# MKW40Z4 register map
Vendor: Freescale Semiconductor, Inc.; Series: Kinetis_W; File version: 1.6
CPU: CM0PLUS r0p0, little endian, no MPU, no FPU, VTOR, 2 interrupt priority bits
Registers are 32-bit, read-write, reset 0x0 unless marked. A register's access mark holds for its fields unless they carry their own. Offsets are from the block's base; [hi:lo] are bit positions; {n}, {i} and the like mark numbered series; 'fields as' and 'values as' point back to an identical list.

## XCVR (part 1 of 2) — Apache 1.0 Transceiver
Base 0x4005C000; register names take the prefix XCVR_
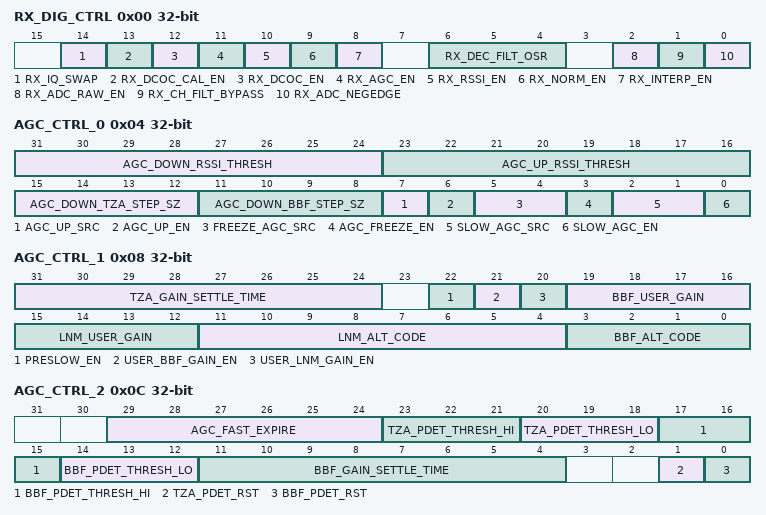
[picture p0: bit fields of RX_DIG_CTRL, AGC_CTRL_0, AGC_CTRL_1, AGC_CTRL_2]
0x00 RX_DIG_CTRL — RX Digital Control
  [14] RX_IQ_SWAP
    0=IQ swap is disabled; 1=IQ swap is enabled
  [13] RX_DCOC_CAL_EN — DCOC Calibration Enable
    0=DCOC calibration is disabled; 1=DCOC calibration is enabled
  [12] RX_DCOC_EN — DCOC Enable
    0=DCOC is disabled; 1=DCOC is enabled
  [11] RX_AGC_EN — AGC Global Enable
    0=AGC is disabled; 1=AGC is enabled
  [10] RX_RSSI_EN — RSSI Measurement Enable
    0=RSSI measurement is disabled; 1=RSSI measurement is enabled
  [9] RX_NORM_EN — Normalizer Enable
    0=Normalizer is disabled; 1=Normalizer is enabled
  [8] RX_INTERP_EN — Interpolator Enable
    0=Interpolator is disabled; 1=Interpolator is enabled
  [6:4] RX_DEC_FILT_OSR — Decimation Filter Oversampling
    0=OSR 2; 1=OSR 4
  [2] RX_ADC_RAW_EN — ADC Raw Mode selection
    0=Normal operation; 1=The decimation filter's 12bit output consists of two unfiltered 5-bit ADC samples. This is for test purposes only to observe ADC output via XCVR DMA or DTEST.
  [1] RX_CH_FILT_BYPASS — Receive Channel Filter Bypass
    0=Channel filter is enabled; 1=Disable and bypass channel filter
  [0] RX_ADC_NEGEDGE — Receive ADC Negative Edge Selection
    0=Register ADC data on positive edge of clock; 1=Register ADC data on negative edge of clock
0x04 AGC_CTRL_0 — AGC Control 0
  [31:24] AGC_DOWN_RSSI_THRESH — AGC DOWN RSSI Threshold
  [23:16] AGC_UP_RSSI_THRESH — AGC UP RSSI Threshold
  [15:12] AGC_DOWN_TZA_STEP_SZ
  [11:8] AGC_DOWN_BBF_STEP_SZ
  [7] AGC_UP_SRC — AGC Up Source
    0=PDET LO; 1=RSSI
  [6] AGC_UP_EN — AGC Up Enable
  [5:4] FREEZE_AGC_SRC — Freeze AGC Source Selection
    0=BTLE Preamble Detect; 1=Zigbee Preamble Detect
  [3] AGC_FREEZE_EN — AGC Freeze Enable
  [2:1] SLOW_AGC_SRC — Slow AGC Source Selection
    0=BTLE Preamble Detect; 1=Zigbee Preamble Detect
  [0] SLOW_AGC_EN — Slow AGC Enable
0x08 AGC_CTRL_1 — AGC Control 1
  [31:24] TZA_GAIN_SETTLE_TIME
  [22] PRESLOW_EN — Pre-slow Enable
    0=Pre-slow is disabled; 1=Pre-slow is enabled
  [21] USER_BBF_GAIN_EN — User BBF Gain Enable
  [20] USER_LNM_GAIN_EN — User LNM Gain Enable
  [19:16] BBF_USER_GAIN
  [15:12] LNM_USER_GAIN
  [11:4] LNM_ALT_CODE
  [3:0] BBF_ALT_CODE
0x0C AGC_CTRL_2 — AGC Control 2
  [29:24] AGC_FAST_EXPIRE
  [23:21] TZA_PDET_THRESH_HI — TZA PDET Threshold High
    0=0.6V; 1=0.675V; 2=0.75V; 3=0.825V; 4=0.9V; 5=0.975V; 6=1.05V; 7=1.125V
  [20:18] TZA_PDET_THRESH_LO — TZA PDET Threshold Low
    values as TZA_PDET_THRESH_HI
  [17:15] BBF_PDET_THRESH_HI — BBF PDET Threshold High
    values as TZA_PDET_THRESH_HI
  [14:12] BBF_PDET_THRESH_LO — BBF PDET Threshold Low
    values as TZA_PDET_THRESH_HI
  [11:4] BBF_GAIN_SETTLE_TIME
  [1] TZA_PDET_RST — TZA PDET Reset
  [0] BBF_PDET_RST — BBF PDET Reset
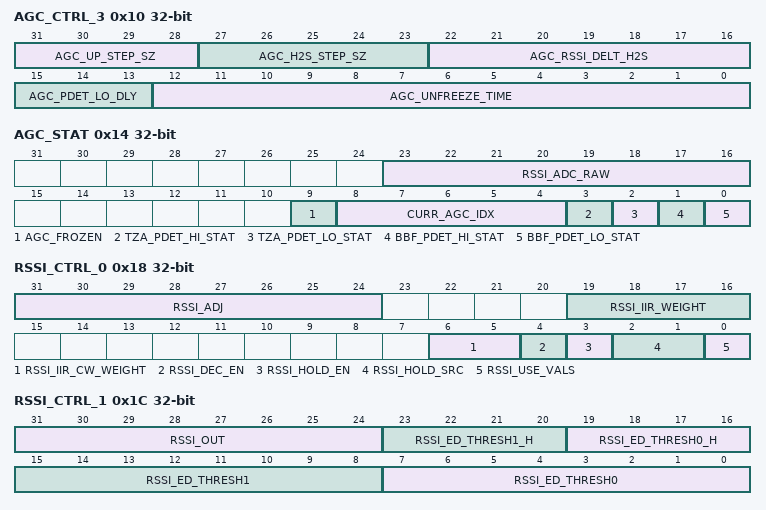
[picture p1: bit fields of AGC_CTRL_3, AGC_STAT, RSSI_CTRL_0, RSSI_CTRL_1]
0x10 AGC_CTRL_3 — AGC Control 3
  [31:28] AGC_UP_STEP_SZ — AGC Up Step Size
  [27:23] AGC_H2S_STEP_SZ
  [22:16] AGC_RSSI_DELT_H2S
  [15:13] AGC_PDET_LO_DLY — AGC Peak Detect Low Delay
  [12:0] AGC_UNFREEZE_TIME
0x14 AGC_STAT ro — AGC Status
  [23:16] RSSI_ADC_RAW — ADC RAW RSSI Reading
  [9] AGC_FROZEN — AGC Frozen Status
    0=AGC is not frozen; 1=AGC is frozen
  [8:4] CURR_AGC_IDX — Current AGC Gain Index
  [3] TZA_PDET_HI_STAT — TZA Peak Detector High Status
  [2] TZA_PDET_LO_STAT — TZA Peak Detector Low Status
  [1] BBF_PDET_HI_STAT — BBF Peak Detector High Status
  [0] BBF_PDET_LO_STAT — BBF Peak Detector Low Status
0x18 RSSI_CTRL_0 — RSSI Control 0
  [31:24] RSSI_ADJ — RSSI Adjustment
  [19:16] RSSI_IIR_WEIGHT — RSSI IIR Weighting
    0=Bypass; 1=1/2
  [6:5] RSSI_IIR_CW_WEIGHT — RSSI IIR CW Weighting
    0=Bypass; 1=1/8
  [4] RSSI_DEC_EN — RSSI Decimation Enable
  [3] RSSI_HOLD_EN — RSSI Hold Enable
  [2:1] RSSI_HOLD_SRC — Hold RSSI Source Selection
    0=BTLE Preamble Detect; 1=Zigbee Preamble Detect
  [0] RSSI_USE_VALS — RSSI Values Selection
0x1C RSSI_CTRL_1 — RSSI Control 1
  [31:24] RSSI_OUT ro — RSSI Reading
  [23:20] RSSI_ED_THRESH1_H — RSSI Energy Detect 1 Hysteresis
  [19:16] RSSI_ED_THRESH0_H — RSSI Energy Detect 0 Hysteresis
  [15:8] RSSI_ED_THRESH1 — RSSI Energy Detect 1 Threshold
  [7:0] RSSI_ED_THRESH0 — RSSI Energy Detect 0 Threshold
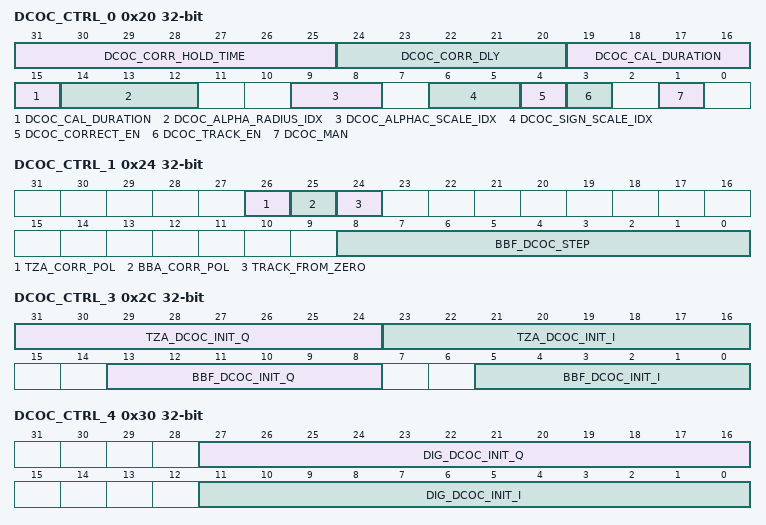
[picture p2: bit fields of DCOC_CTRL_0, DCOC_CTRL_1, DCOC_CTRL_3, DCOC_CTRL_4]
0x20 DCOC_CTRL_0 — DCOC Control 0
  [31:25] DCOC_CORR_HOLD_TIME — DCOC Correction Hold Time
  [24:20] DCOC_CORR_DLY — DCOC Correction Delay
  [19:15] DCOC_CAL_DURATION — DCOC Calibration Duration
  [14:12] DCOC_ALPHA_RADIUS_IDX — Alpha-R Scaling
    0=1; 1=1/2; 2=1/4; 3=1/8; 4=1/16; 5=1/32; 6=1/64
  [9:8] DCOC_ALPHAC_SCALE_IDX — DCOC Alpha-C Scaling
    0=1/2; 1=1/4; 2=1/8; 3=1/16
  [6:5] DCOC_SIGN_SCALE_IDX — DCOC Sign Scaling
    0=1/4; 1=1/8; 2=1/16; 3=1/32
  [4] DCOC_CORRECT_EN — DCOC Correction Enable
  [3] DCOC_TRACK_EN — DCOC Tracking Enable
  [1] DCOC_MAN — DCOC Manual Override
0x24 DCOC_CTRL_1 — DCOC Control 1
  [26] TZA_CORR_POL — TZA Correction Polarity
    0=Normal polarity; 1=Negative polarity. This should be set if the ADC output is inverted, or if the TZA DACs were implemented with negative polarity.
  [25] BBA_CORR_POL — BBA Correction Polarity
    0=Normal polarity; 1=Negative polarity. This should be set if the ADC output is inverted, or if the BBA DACs were implemented with negative polarity.
  [24] TRACK_FROM_ZERO
    0=Track from current I/Q sample; 1=Track from zero
  [8:0] BBF_DCOC_STEP — DCOC BBF Step Size
0x28 DCOC_CTRL_2 — DCOC Control 2
  [12:0] BBF_DCOC_STEP_RECIP — DCOC BBF Reciprocal of Step Size
0x2C DCOC_CTRL_3 — DCOC Control 3
  [31:24] TZA_DCOC_INIT_Q — DCOC TZA Init Q
  [23:16] TZA_DCOC_INIT_I — DCOC TZA Init I
  [13:8] BBF_DCOC_INIT_Q — DCOC BBF Init Q
  [5:0] BBF_DCOC_INIT_I — DCOC BBF Init I
0x30 DCOC_CTRL_4 — DCOC Control 4
  [27:16] DIG_DCOC_INIT_Q — DCOC DIG Init Q
  [11:0] DIG_DCOC_INIT_I — DCOC DIG Init I
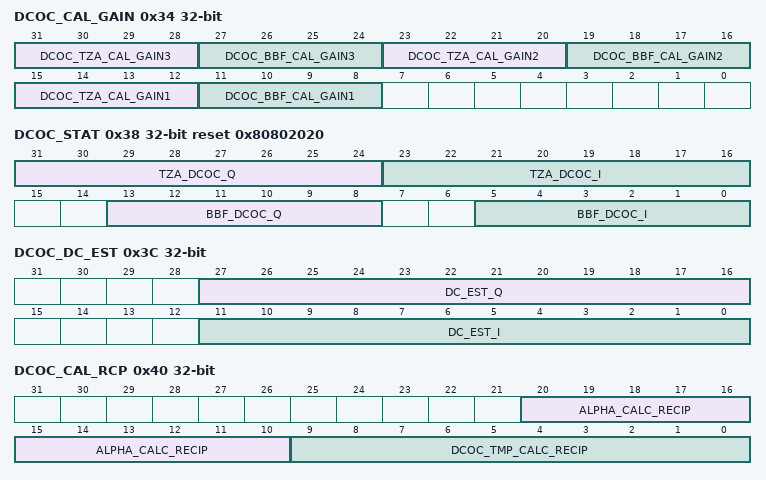
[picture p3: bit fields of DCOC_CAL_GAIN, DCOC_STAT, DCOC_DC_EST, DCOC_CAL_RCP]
0x34 DCOC_CAL_GAIN — DCOC Calibration Gain
  [31:28] DCOC_TZA_CAL_GAIN3 — DCOC TZA Calibration Gain 3
  [27:24] DCOC_BBF_CAL_GAIN3 — DCOC BBF Calibration Gain 3
  [23:20] DCOC_TZA_CAL_GAIN2 — DCOC TZA Calibration Gain 2
  [19:16] DCOC_BBF_CAL_GAIN2 — DCOC BBF Calibration Gain 2
  [15:12] DCOC_TZA_CAL_GAIN1 — DCOC TZA Calibration Gain 1
  [11:8] DCOC_BBF_CAL_GAIN1 — DCOC BBF Calibration Gain 1
0x38 DCOC_STAT ro reset 0x80802020 — DCOC Status
  [31:24] TZA_DCOC_Q — DCOC TZA DAC Q
  [23:16] TZA_DCOC_I — DCOC TZA DAC I
  [13:8] BBF_DCOC_Q — DCOC BBF DAC Q
  [5:0] BBF_DCOC_I — DCOC BBF DAC I
0x3C DCOC_DC_EST ro — DCOC DC Estimate
  [27:16] DC_EST_Q — DCOC DC Estimate Q
  [11:0] DC_EST_I — DCOC DC Estimate I
0x40 DCOC_CAL_RCP — DCOC Calibration Reciprocals
  [20:10] ALPHA_CALC_RECIP — Alpha Calculation Reciprocal
  [9:0] DCOC_TMP_CALC_RECIP — DCOC Calculation Reciprocal
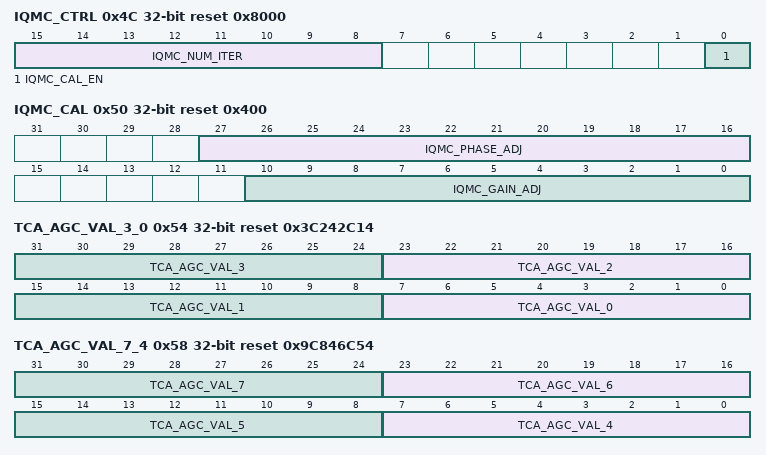
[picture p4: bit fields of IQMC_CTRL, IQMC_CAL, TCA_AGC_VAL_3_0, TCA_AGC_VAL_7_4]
0x4C IQMC_CTRL reset 0x8000 — IQMC Control
  [15:8] IQMC_NUM_ITER — IQ Mismatch Cal Num Iter
  [0] IQMC_CAL_EN — IQ Mismatch Cal Enable
0x50 IQMC_CAL reset 0x400 — IQMC Calibration
  [27:16] IQMC_PHASE_ADJ — IQ Mismatch Correction Phase Coeff
  [10:0] IQMC_GAIN_ADJ — IQ Mismatch Correction Gain Coeff
0x54 TCA_AGC_VAL_3_0 reset 0x3C242C14 — TCA AGC Step Values 3..0
  [8n+7:8n] TCA_AGC_VAL_{n} (n=0..3) — TCA_AGC step {n}
0x58 TCA_AGC_VAL_7_4 reset 0x9C846C54 — TCA AGC Step Values 7..4
  [8n-25:8n-32] TCA_AGC_VAL_{n} (n=4..7) — TCA_AGC step {n}
0x5C TCA_AGC_VAL_8 reset 0xB4 — TCA AGC Step Values 8
  [7:0] TCA_AGC_VAL_8 — TCA_AGC step 8
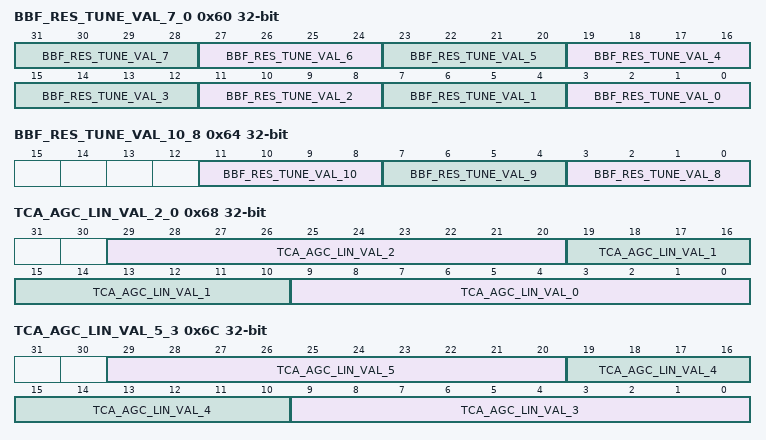
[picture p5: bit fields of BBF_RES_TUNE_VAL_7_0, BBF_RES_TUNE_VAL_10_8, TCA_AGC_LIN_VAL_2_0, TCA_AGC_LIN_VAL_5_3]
0x60 BBF_RES_TUNE_VAL_7_0 — BBF Resistor Tune Values 7..0
  [4n+3:4n] BBF_RES_TUNE_VAL_{n} (n=0..7) — BBF Resistor Tune Step {n}
0x64 BBF_RES_TUNE_VAL_10_8 — BBF Resistor Tune Values 10..8
  [11:8] BBF_RES_TUNE_VAL_10 — BBF Resistor Tune Step 10
  [7:4] BBF_RES_TUNE_VAL_9 — BBF Resistor Tune Step 9
  [3:0] BBF_RES_TUNE_VAL_8 — BBF Resistor Tune Step 8
0x68 TCA_AGC_LIN_VAL_2_0 — TCA AGC Linear Gain Values 2..0
  [29:20] TCA_AGC_LIN_VAL_2 — TCA AGC Linear Gain Step 2
  [19:10] TCA_AGC_LIN_VAL_1 — TCA AGC Linear Gain Step 1
  [9:0] TCA_AGC_LIN_VAL_0 — LNM linear gain value for index 0, e.g. nominal value is 10^(-3/20). Stored with 2 fractional bits, e.g. round([10^(-3/20)]*2^2) = 3decimal
0x6C TCA_AGC_LIN_VAL_5_3 — TCA AGC Linear Gain Values 5..3
  [29:20] TCA_AGC_LIN_VAL_5 — TCA AGC Linear Gain Step 5
  [19:10] TCA_AGC_LIN_VAL_4 — TCA AGC Linear Gain Step 4
  [9:0] TCA_AGC_LIN_VAL_3 — TCA AGC Linear Gain Step 3
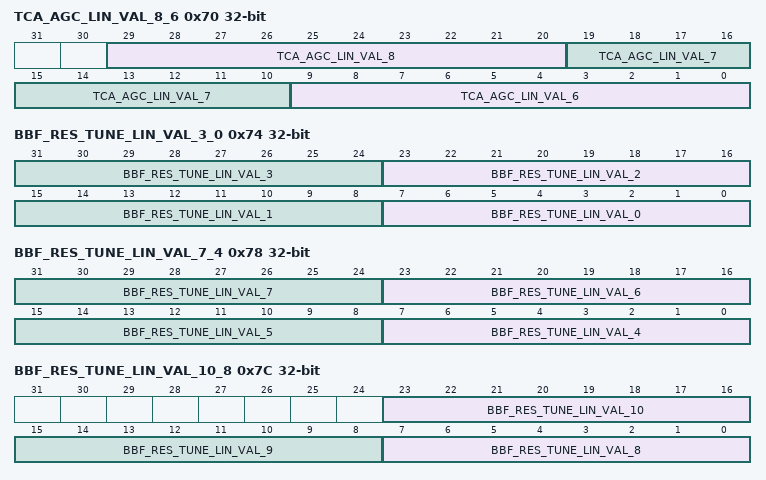
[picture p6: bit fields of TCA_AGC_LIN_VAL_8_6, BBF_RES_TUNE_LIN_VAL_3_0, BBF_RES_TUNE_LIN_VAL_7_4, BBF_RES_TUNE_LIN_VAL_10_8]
0x70 TCA_AGC_LIN_VAL_8_6 — TCA AGC Linear Gain Values 8..6
  [29:20] TCA_AGC_LIN_VAL_8 — TCA AGC Linear Gain Step 8
  [19:10] TCA_AGC_LIN_VAL_7 — TCA AGC Linear Gain Step 7
  [9:0] TCA_AGC_LIN_VAL_6 — TCA AGC Linear Gain Step 6
0x74 BBF_RES_TUNE_LIN_VAL_3_0 — BBF Resistor Tune Values 3..0
  [8n+7:8n] BBF_RES_TUNE_LIN_VAL_{n} (n=0..3) — BBF Resistor Tune Linear Gain Step {n}
0x78 BBF_RES_TUNE_LIN_VAL_7_4 — BBF Resistor Tune Values 7..4
  [8n-25:8n-32] BBF_RES_TUNE_LIN_VAL_{n} (n=4..7) — BBF Resistor Tune Linear Gain Step {n}
0x7C BBF_RES_TUNE_LIN_VAL_10_8 — BBF Resistor Tune Values 10..8
  [23:16] BBF_RES_TUNE_LIN_VAL_10 — BBF Resistor Tune Linear Gain Step 10
  [15:8] BBF_RES_TUNE_LIN_VAL_9 — BBF Resistor Tune Linear Gain Step 9
  [7:0] BBF_RES_TUNE_LIN_VAL_8 — BBF Resistor Tune Linear Gain Step 8
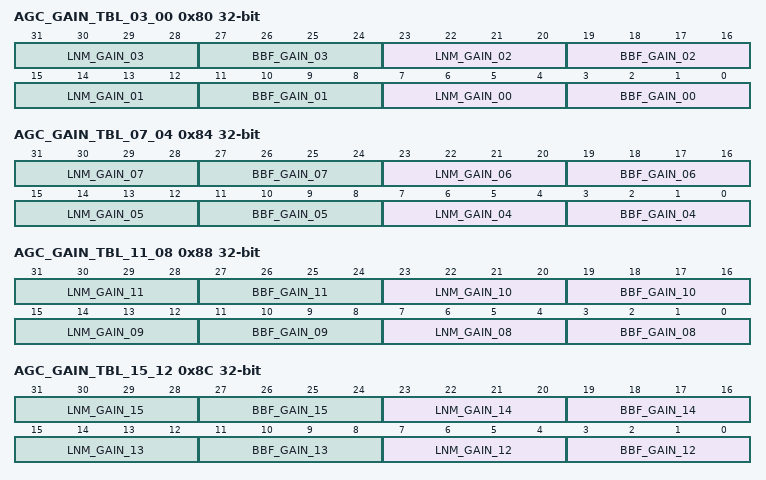
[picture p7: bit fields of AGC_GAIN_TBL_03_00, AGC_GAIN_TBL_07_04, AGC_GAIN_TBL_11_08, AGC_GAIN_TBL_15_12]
0x80 AGC_GAIN_TBL_03_00 — AGC Gain Tables Step 03..00
  [8n+7:8n+4] LNM_GAIN_{n:02} (n=0..3), [8n+3:8n] BBF_GAIN_{n:02} (n=0..3)
0x84 AGC_GAIN_TBL_07_04 — AGC Gain Tables Step 07..04
  [8n-25:8n-28] LNM_GAIN_{n:02} (n=4..7), [8n-29:8n-32] BBF_GAIN_{n:02} (n=4..7)
0x88 AGC_GAIN_TBL_11_08 — AGC Gain Tables Step 11..08
  [8n-57:8n-60] LNM_GAIN_{n:02} (n=8..11), [8n-61:8n-64] BBF_GAIN_{n:02} (n=8..11)
0x8C AGC_GAIN_TBL_15_12 — AGC Gain Tables Step 15..12
  [8n-89:8n-92] LNM_GAIN_{n} (n=12..15), [8n-93:8n-96] BBF_GAIN_{n} (n=12..15)
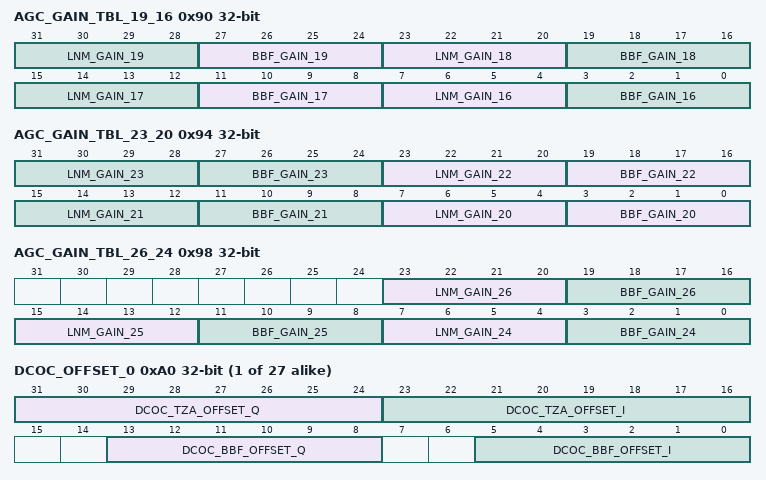
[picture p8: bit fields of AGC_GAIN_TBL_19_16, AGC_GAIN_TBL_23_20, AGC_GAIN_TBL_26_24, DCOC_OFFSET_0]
0x90 AGC_GAIN_TBL_19_16 — AGC Gain Tables Step 19..16
  [8n-121:8n-124] LNM_GAIN_{n} (n=16..19)
  [27:24] BBF_GAIN_19 — BBF Gain 193
  [19:16] BBF_GAIN_18
  [11:8] BBF_GAIN_17
  [3:0] BBF_GAIN_16
0x94 AGC_GAIN_TBL_23_20 — AGC Gain Tables Step 23..20
  [8n-153:8n-156] LNM_GAIN_{n} (n=20..23), [8n-157:8n-160] BBF_GAIN_{n} (n=20..23)
0x98 AGC_GAIN_TBL_26_24 — AGC Gain Tables Step 26..24
  [23:20] LNM_GAIN_26, [19:16] BBF_GAIN_26, [15:12] LNM_GAIN_25, [11:8] BBF_GAIN_25, [7:4] LNM_GAIN_24, [3:0] BBF_GAIN_24
{0xA0+4i} DCOC_OFFSET_{i} (i=0..26)
  [31:24] DCOC_TZA_OFFSET_Q — DCOC TZA Q-channel offset
  [23:16] DCOC_TZA_OFFSET_I — DCOC TZA I-channel offset
  [13:8] DCOC_BBF_OFFSET_Q — DCOC BBF Q-channel offset
  [5:0] DCOC_BBF_OFFSET_I — DCOC BBF I-channel offset
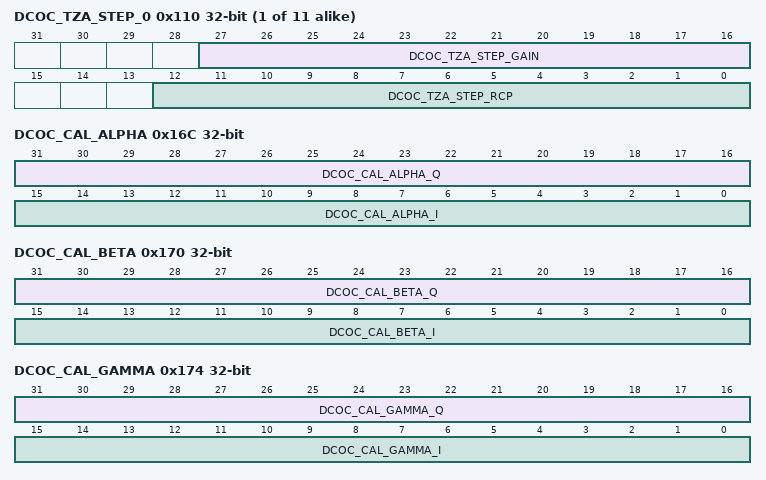
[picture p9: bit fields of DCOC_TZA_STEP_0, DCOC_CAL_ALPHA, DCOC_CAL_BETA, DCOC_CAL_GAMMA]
{0x110+4i} DCOC_TZA_STEP_{i} (i=0..10) — DCOC TZA DC step
  [27:16] DCOC_TZA_STEP_GAIN, [12:0] DCOC_TZA_STEP_RCP
0x16C DCOC_CAL_ALPHA ro — DCOC Calibration Alpha
  [31:16] DCOC_CAL_ALPHA_Q
  [15:0] DCOC_CAL_ALPHA_I — DCOC Calibration I-channel ALPHA constant
0x170 DCOC_CAL_BETA ro — DCOC Calibration Beta
  [31:16] DCOC_CAL_BETA_Q, [15:0] DCOC_CAL_BETA_I
0x174 DCOC_CAL_GAMMA ro — DCOC Calibration Gamma
  [31:16] DCOC_CAL_GAMMA_Q, [15:0] DCOC_CAL_GAMMA_I
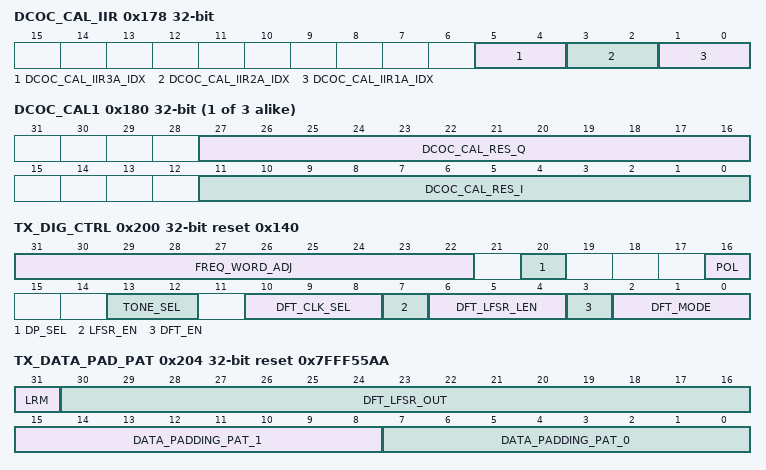
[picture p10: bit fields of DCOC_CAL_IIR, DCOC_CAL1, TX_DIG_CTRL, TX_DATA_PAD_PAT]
0x178 DCOC_CAL_IIR — DCOC Calibration IIR
  [5:4] DCOC_CAL_IIR3A_IDX — DCOC Calibration IIR 3A Index
    0=1/4; 1=1/8
  [3:2] DCOC_CAL_IIR2A_IDX — DCOC Calibration IIR 2A Index
    0=1/1; 1=1/4
  [1:0] DCOC_CAL_IIR1A_IDX — DCOC Calibration IIR 1A Index
    0=1/1; 1=1/4
{0x17C+4i} DCOC_CAL{i} (i=1..3) ro — DCOC Calibration Result
  [27:16] DCOC_CAL_RES_Q — DCOC Calibration Result - Q Channel
  [11:0] DCOC_CAL_RES_I — DCOC Calibration Result - I Channel
{0x1A0+4i} RX_CHF_COEF{i} (i=0..7) — Receive Channel Filter Coefficient
  [7:0] RX_CH_FILT_HX — RX Channel Filter Coefficient
0x200 TX_DIG_CTRL reset 0x140 — TX Digital Control
  [31:22] FREQ_WORD_ADJ — GFSK Frequency Word Adjustment
  [20] DP_SEL — Data Padding Pattern Select
    0=Selects DATA_PADDING_PATTERN_0 as the source for data padding; 1=Selects DATA_PADDING_PATTERN_1 as the source for data padding
  [16] POL — Oversample Clock Capture Polarity
    0=Selects Even clock cycle; 1=Selects Odd clock cycle, a one cycle delay
  [13:12] TONE_SEL — DFT Tone Selection
    {v}=DFT Tone {v} (v=0..3)
  [10:8] DFT_CLK_SEL — DFT Clock Selection
    0=62.5 kHz; 1=125 kHz; 2=250 kHz; 3=500 kHz; 4=1 MHz; 5=2 MHz; 6=4 MHz; 7=Clock is off
  [7] LFSR_EN — DFT LFSR Enable
  [6:4] DFT_LFSR_LEN — DFT LFSR Length
    0=LFSR 9, tap mask 100010000; 1=LFSR 10, tap mask 1001000000; 2=LFSR 11, tap mask 11101000000; 3=LFSR 13, tap mask 1101100000000; 4=LFSR 15, tap mask 111010000000000; 5=LFSR 17, tap mask 11110000000000000
  [3] DFT_EN — Radio DFT Mode Enable
  [2:0] DFT_MODE — Radio DFT Modes
    0=Normal Radio Operation. DFT not engaged.; 1=Pattern Register Mode. TX DFT Modulation Pattern Register is shifted out as the transmission data stream. Note that the DFT_EN bit must be set.; 2=LFSR Data Mode. TX LFSR is used as the transmission data stream. Note that the LFSR_EN bit must be set.; 3=LFSR Symbol Mode. TX LFSR is used to create 802.15.4 symbols which are then converted to Chips and transmitted. Note that the LFSR_EN bit must be set.; 4=Not implemented on Apache 1.0, future use will allow a package pin to be used as the source of the TX data stream. Note that the DFT_EN bit must be set.; 5=Constant Frequency Mode. No data modulation is done, Radio transmits at the channel frequency selected.; 6=LFSR Tone Mode. TX LFSR is used to select the DFT Tone register to transmit, LFSR_EN bit must be set.; 7=Manual Tone Mode. TONE_SEL is used to select the DFT Tone register to transmit.
0x204 TX_DATA_PAD_PAT reset 0x7FFF55AA — TX Data Padding Pattern
  [31] LRM — LFSR Reset Mask
  [30:16] DFT_LFSR_OUT ro — Transmit DFT LFSR Output
  [15:8] DATA_PADDING_PAT_1 — Data Padding Pattern 1
  [7:0] DATA_PADDING_PAT_0 — Data Padding Pattern 0
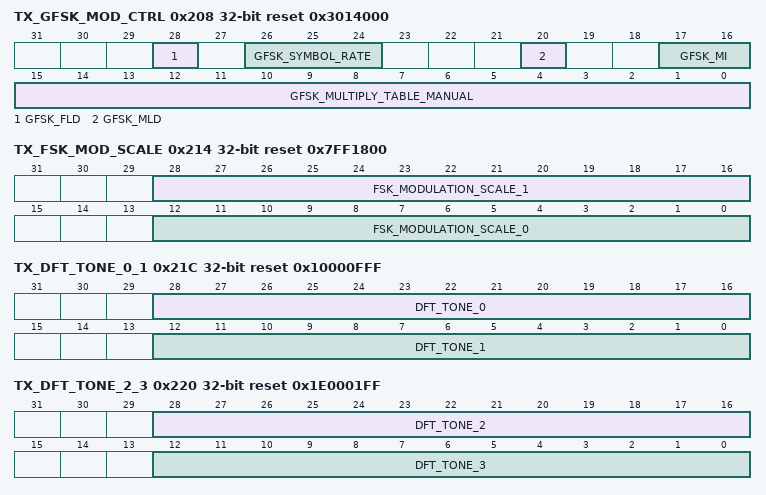
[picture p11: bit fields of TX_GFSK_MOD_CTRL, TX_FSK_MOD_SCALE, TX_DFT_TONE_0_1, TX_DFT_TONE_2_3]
0x208 TX_GFSK_MOD_CTRL reset 0x3014000 — TX GFSK Modulation Control
  [28] GFSK_FLD — GFSK Filter Lookup Table Disable
  [26:24] GFSK_SYMBOL_RATE
    0=50 kHz; 1=100 kHz; 2=200 kHz; 3=1 MHz; 4=2 MHz
  [20] GFSK_MLD — GFSK Multiply Lookup Table Disable
  [17:16] GFSK_MI — GFSK Modulation Index
    0=0.32; 1=0.50; 2=0.80; 3=1.00
  [15:0] GFSK_MULTIPLY_TABLE_MANUAL — GFSK Multiply Lookup Table Override Value
0x20C TX_GFSK_COEFF2 reset 0xC0630401 — TX GFSK Filter Coefficients 2
  [31:0] GFSK_FILTER_COEFF_MANUAL2 — GFSK Manual Filter Coefficients[63:32]
0x210 TX_GFSK_COEFF1 reset 0xBB29960D — TX GFSK Filter Coefficients 1
  [31:0] GFSK_FILTER_COEFF_MANUAL1 — GFSK Manual Filter Coefficient [31:0]
0x214 TX_FSK_MOD_SCALE reset 0x7FF1800 — TX FSK Modulation Scale
  [28:16] FSK_MODULATION_SCALE_1 — FSK Modulation Scale for a data 1
  [12:0] FSK_MODULATION_SCALE_0 — FSK Modulation Scale for a data 0
0x218 TX_DFT_MOD_PAT — TX DFT Modulation Pattern
  [31:0] DFT_MOD_PATTERN — DFT Modulation Pattern
0x21C TX_DFT_TONE_0_1 reset 0x10000FFF — TX DFT Tones 0 and 1
  [28:16] DFT_TONE_0, [12:0] DFT_TONE_1
0x220 TX_DFT_TONE_2_3 reset 0x1E0001FF — TX DFT Tones 2 and 3
  [28:16] DFT_TONE_2, [12:0] DFT_TONE_3
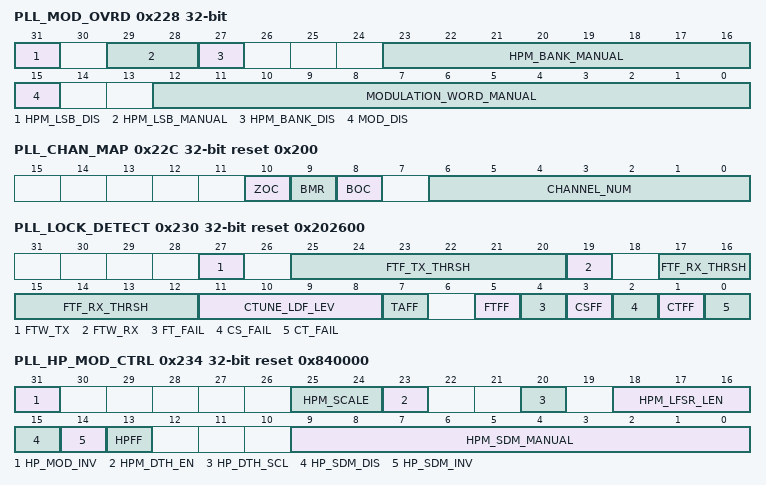
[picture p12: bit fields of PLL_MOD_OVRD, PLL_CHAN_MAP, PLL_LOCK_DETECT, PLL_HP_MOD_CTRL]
0x228 PLL_MOD_OVRD — PLL Modulation Overrides
  [31] HPM_LSB_DIS — Disable HPM LSB
  [29:28] HPM_LSB_MANUAL — Manual HPM LSB
  [27] HPM_BANK_DIS — Disable HPM Bank
  [23:16] HPM_BANK_MANUAL — Manual HPM bank
  [15] MOD_DIS — Disable Modulation Word
  [12:0] MODULATION_WORD_MANUAL — Manual Modulation Word
0x22C PLL_CHAN_MAP reset 0x200 — PLL Channel Mapping
  [10] ZOC — Zigbee Channel Number Override
    0=Zigbee channel number comes from the 802.15.4 Link Layer; 1=Zigbee channel number comes from the CHANNEL_NUM register
  [9] BMR — BLE MBAN Channel Remap
    0=BLE channel 39 is mapped to BLE channel 39, 2.480 GHz; 1=BLE channel 39 is mapped to MBAN channel 39, 2.399 GHz
  [8] BOC — BLE Channel Number Override
    0=BLE channel number comes from the BLE Link Layer; 1=BLE channel number comes from the CHANNEL_NUM register
  [6:0] CHANNEL_NUM — Protocol specific Channel Number for PLL Frequency Mapping
0x230 PLL_LOCK_DETECT reset 0x202600
  [27] FTW_TX — TX Frequency Target Window time select
    0=4 us; 1=8 us
  [25:20] FTF_TX_THRSH — TX Frequency Target Fail Threshold
  [19] FTW_RX — RX Frequency Target Window time select
    0=4 us; 1=8 us
  [17:12] FTF_RX_THRSH — RX Frequency Target Fail Threshold
  [11:8] CTUNE_LDF_LEV — CTUNE Lock Detect Fail Level
  [7] TAFF — TSM Abort Failure Flag
  [5] FTFF — Frequency Target Failure Flag
  [4] FT_FAIL ro — Real time status of Frequency Target Failure
  [3] CSFF — Cycle Slip Failure Flag, held until cleared
  [2] CS_FAIL ro — Real time status of Cycle Slip circuit
  [1] CTFF — CTUNE Failure Flag, held until cleared
  [0] CT_FAIL ro — Real time status of Coarse Tune Fail signal
0x234 PLL_HP_MOD_CTRL reset 0x840000 — PLL High Port Modulation Control
  [31] HP_MOD_INV — HPM Invert
  [25:24] HPM_SCALE — HPM Scale Factor
    0=No Scaling; 1=Multiply by 2; 2=Divide by 2
  [23] HPM_DTH_EN — Dither Enable for HPM LFSR
  [20] HP_DTH_SCL — HPM Dither Scale
  [18:16] HPM_LFSR_LEN — HPM LFSR Length
    values as TX_DIG_CTRL.DFT_LFSR_LEN
  [15] HP_SDM_DIS — Disable HPM SDM
  [14] HP_SDM_INV — Invert HPM SDM
  [13] HPFF — HPM SDM Invalid Flag
  [9:0] HPM_SDM_MANUAL — PLL HPM SDM MANUAL
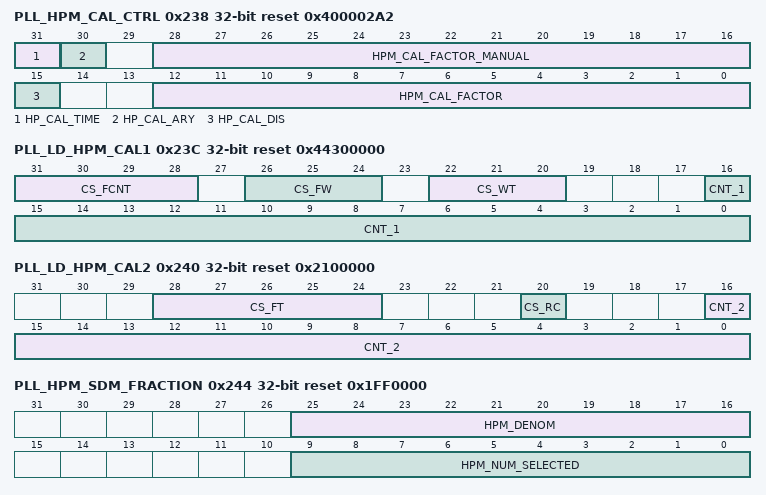
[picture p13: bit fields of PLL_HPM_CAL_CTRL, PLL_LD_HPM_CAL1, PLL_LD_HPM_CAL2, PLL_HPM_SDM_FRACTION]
0x238 PLL_HPM_CAL_CTRL reset 0x400002A2 — PLL HPM Calibration Control
  [31] HP_CAL_TIME — High Port Modulation Calibration Time
    0=25 us; 1=50 us
  [30] HP_CAL_ARY — High Port Modulation Calibration Array Size
    0=128; 1=256
  [28:16] HPM_CAL_FACTOR_MANUAL — HPM Manual Calibration Factor
  [15] HP_CAL_DIS — If this bit is set, the lookup table value for the HPM Calibration Factor is overridden by the HPM_CAL_FACTOR_MANUAL register
  [12:0] HPM_CAL_FACTOR ro — High Port Modulation Calibration Factor
0x23C PLL_LD_HPM_CAL1 reset 0x44300000 — PLL Cycle Slip Lock Detect Configuration and HPM Calibration 1
  [31:28] CS_FCNT — Cycle Slip Flag Count
  [26:24] CS_FW — Cycle Slip Flag Window
    0=8 us; 1=16 us; 2=24 us; 3=32 us; 4=64 us; 5=96 us; 6=128 us; 7=256 us
  [22:20] CS_WT — Cycle Slip Wait Time
    0=128 us; 1=256 us; 2=384 us; 3=512 us; 4=640 us; 5=768 us; 6=896 us; 7=1024 us
  [16:0] CNT_1 ro — High Port Modulation Counter Value 1
0x240 PLL_LD_HPM_CAL2 reset 0x2100000 — PLL Cycle Slip Lock Detect Configuration and HPM Calibration 2
  [28:24] CS_FT — Cycle Slip Flag Timeout
  [20] CS_RC — Cycle Slip Recycle
  [16:0] CNT_2 ro — High Port Modulation Counter Value 2
0x244 PLL_HPM_SDM_FRACTION reset 0x1FF0000
  [25:16] HPM_DENOM — High Port Modulation Denominator
  [9:0] HPM_NUM_SELECTED ro
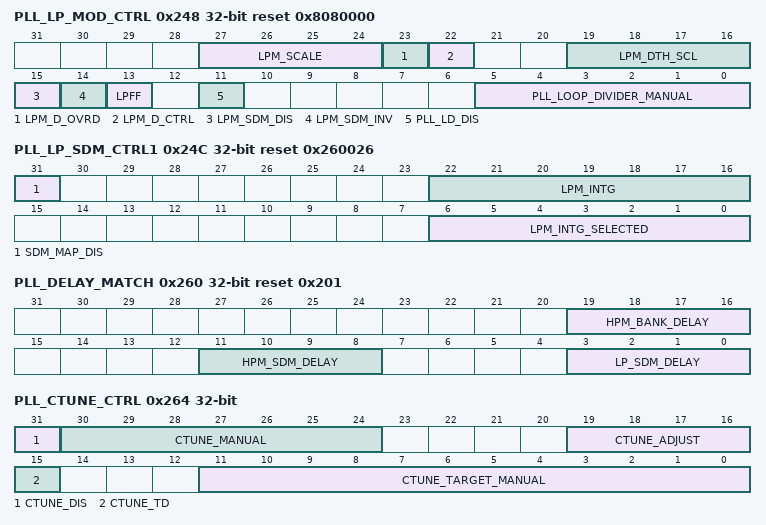
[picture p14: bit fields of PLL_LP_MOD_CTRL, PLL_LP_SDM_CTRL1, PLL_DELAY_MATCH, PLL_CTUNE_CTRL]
0x248 PLL_LP_MOD_CTRL reset 0x8080000 — PLL Low Port Modulation Control
  [27:24] LPM_SCALE — LPM Scale Factor
    0=No Scaling; 1=Multiply by 2; 2=Multiply by 4; 3=Multiply by 8; 4=Multiply by 16; 5=Multiply by 32; 6=Multiply by 64; 7=Multiply by 128; 8=Multiply by 256; 9=Multiply by 512; 10=Multiply by 1024; 11=Multiply by 2048
  [23] LPM_D_OVRD — LPM Dither Override Mode Select
  [22] LPM_D_CTRL — LPM Dither Control in Override Mode
  [19:16] LPM_DTH_SCL — LPM Dither Scale
    5=-128 to 96; 6=-256 to 192; 7=-512 to 384; 8=-1024 to 768; 9=-2048 to 1536; 10=-4096 to 3072; 11=-8192 to 6144
  [15] LPM_SDM_DIS — Disable LPM SDM
  [14] LPM_SDM_INV — Invert LPM SDM
  [13] LPFF — LPM SDM Invalid Flag
  [11] PLL_LD_DIS — PLL Loop Divider Disable
  [5:0] PLL_LOOP_DIVIDER_MANUAL
0x24C PLL_LP_SDM_CTRL1 reset 0x260026 — PLL Low Port SDM Control 1
  [31] SDM_MAP_DIS — SDM Mapping Disable
  [22:16] LPM_INTG — Low Port Modulation Integer Manual Value
  [6:0] LPM_INTG_SELECTED ro — Low Port Modulation Integer Value Selected
0x250 PLL_LP_SDM_CTRL2 reset 0x2000000 — PLL Low Port SDM Control 2
  [27:0] LPM_NUM — Low Port Modulation Numerator
0x254 PLL_LP_SDM_CTRL3 reset 0x4000000 — PLL Low Port SDM Control 3
  [27:0] LPM_DENOM — Low Port Modulation Denominator
0x258 PLL_LP_SDM_NUM ro reset 0xE200000 — PLL Low Port SDM Numerator Applied
  [27:0] LPM_NUM_SELECTED — Low Port Modulation Numerator Applied
0x25C PLL_LP_SDM_DENOM ro reset 0x4000000 — PLL Low Port SDM Denominator Applied
  [27:0] LPM_DENOM_SELECTED — Low Port Modulation Denominator Selected
0x260 PLL_DELAY_MATCH reset 0x201 — PLL Delay Matching
  [19:16] HPM_BANK_DELAY, [11:8] HPM_SDM_DELAY, [3:0] LP_SDM_DELAY
0x264 PLL_CTUNE_CTRL — PLL Coarse Tune Control
  [31] CTUNE_DIS — CTUNE Disable
  [30:24] CTUNE_MANUAL
  [19:16] CTUNE_ADJUST — CTUNE Count Adjustment
  [15] CTUNE_TD — CTUNE Target Disable
  [11:0] CTUNE_TARGET_MANUAL
0x268 PLL_CTUNE_CNT6 ro — PLL Coarse Tune Count 6
  [11:0] CTUNE_COUNT_6
0x26C PLL_CTUNE_CNT5_4 ro — PLL Coarse Tune Counts 5 and 4
  [27:16] CTUNE_COUNT_5, [11:0] CTUNE_COUNT_4
0x270 PLL_CTUNE_CNT3_2 ro — PLL Coarse Tune Counts 3 and 2
  [27:16] CTUNE_COUNT_3, [11:0] CTUNE_COUNT_2
0x274 PLL_CTUNE_CNT1_0 ro — PLL Coarse Tune Counts 1 and 0
  [27:16] CTUNE_COUNT_1, [11:0] CTUNE_COUNT_0
0x278 PLL_CTUNE_RESULTS ro reset 0x9620040 — PLL Coarse Tune Results
  [27:16] CTUNE_FREQ_TARGET — Coarse Tune Frequency Target
  [15:8] CTUNE_BEST_DIFF — Coarse Tune Absolute Best Difference
  [6:0] CTUNE_SELECTED — Coarse Tune Band to VCO
0x280 CTRL — Transceiver Control
  [7:6] REF_CLK_FREQ — Radio Reference Clock Frequency
    0=32 MHz
  [5:4] TGT_PWR_SRC — Target Power Source
  [2:0] PROTOCOL — Radio Protocol Selection
    0=BLE; 1=BLE in MBAN; 2=BLE overlap MBAN; 4=Zigbee; 5=802.15.4j; 6=128 Channel FSK; 7=128 Channel GFSK
0x284 STATUS ro (reset mask 0xFFF0CFFF) — Transceiver Status
  [19] SOC_USING_RF_OSC_CLK — SOC Using RF Clock Indication
  [18] XTAL_READY — RF Osciallator Xtal Ready
    0=Indicates that the RF Oscillator is disabled or has not completed its warmup; 1=Indicates that the RF Oscillator has completed its warmup count and is ready for use
  [17] RIF_LL_ACTIVE — Link Layer Active Indication
  [16] BTLE_SYSCLK_REQ — BTLE System Clock Request
  [13] TX_MODE — Transmit Mode
  [12] RX_MODE — Receive Mode
  [11:8] PLL_SEQ_STATE — PLL Sequence State
    0=PLL OFF; 2=HPMCAL2
  [7:0] TSM_COUNT
0x288 SOFT_RESET ro
0x290 OVERWRITE_VER — Overwrite Version
  [7:0] OVERWRITE_VER — Overwrite Version Number.
0x294 DMA_CTRL — DMA Control
  [1] DMA_Q_EN — DMA Q Enable
    0=Transceiver Q channel DMA disabled; 1=Enable the transceiver DMA engine to store RX_DIG Q channel outputs to system memory
  [0] DMA_I_EN — DMA I Enable
    0=Transceiver I channel DMA disabled; 1=Enable the transceiver DMA engine to store RX_DIG I channel outputs to system memory
0x298 DMA_DATA ro
  [27:16] DMA_DATA_27_16, [11:0] DMA_DATA_11_0
0x29C DTEST_CTRL — Digital Test Control
  [29] RAW_MODE_Q — DTEST Raw Mode Enable for Q Channel
  [28] RAW_MODE_I — DTEST Raw Mode Enable for I Channel
  [26:24] DTEST_SHFT — DTEST Shift Control
  [17] TSM_GPIO_OVLAY_1 — TSM GPIO 1 Overlay Pin
    0=there is no overlay, and the DTEST Page Table dictates the node that appears on each DTEST pin; 1=the register GPIO1_OVLAY_PIN[3:0] selects the DTEST pin on which GPIO1_TRIG_EN will appear
  [16] TSM_GPIO_OVLAY_0 — TSM GPIO 0 Overlay Pin
    0=there is no overlay, and the DTEST Page Table dictates the node that appears on each DTEST pin; 1=the register GPIO0_OVLAY_PIN[3:0] selects the DTEST pin on which GPIO0_TRIG_EN will appear
  [15:12] GPIO1_OVLAY_PIN — GPIO 1 Overlay Pin
  [11:8] GPIO0_OVLAY_PIN — GPIO 0 Overlay Pin
  [7] DTEST_EN — DTEST Enable
    0=Disables DTEST. The IC's DTEST pins assume their mission function.; 1=Enables DTEST. The contents of the selected page (DTEST_PAGE) will appear on the IC's DTEST output pins.
  [5:0] DTEST_PAGE — DTEST Page Selector
0x2A0 PB_CTRL — Packet Buffer Control Register
  [0] PB_PROTECT
    0=Incoming received packets overwrite Packet Buffer contents (default); 1=Incoming received packets are blocked from overwriting Packet Buffer contents
0x2C0 TSM_CTRL reset 0xFF000000 — Transceiver Sequence Manager Control
  [31:24] BKPT — TSM Breakpoint
  [20] ABORT_ON_FREQ_TARG — Abort On Frequency Target Lock Detect Failure
    0=don't allow TSM abort on Frequency Target Unlock Detect; 1=allow TSM abort on Frequency Target Unlock Detect
  [19] ABORT_ON_CYCLE_SLIP — Abort On Cycle Slip Lock Detect Failure
    0=don't allow TSM abort on Cycle Slip Unlock Detect; 1=allow TSM abort on Cycle Slip Unlock Detect
  [18] ABORT_ON_CTUNE — Abort On Coarse Tune Lock Detect Failure
    0=don't allow TSM abort on Coarse Tune Unlock Detect; 1=allow TSM abort on Coarse Tune Unlock Detect
  [17] RX_ABORT_DIS — Receive Abort Disable
  [16] TX_ABORT_DIS — Transmit Abort Disable
  [6] DATA_PADDING_EN — Data Padding Enable
    0=Disable TX Data Padding; 1=Enable TX Data Padding
  [5:4] PA_RAMP_SEL — PA Ramp Selection
  [3] FORCE_RX_EN — Force Receive Enable
    0=TSM Idle; 1=TSM executes a RX sequence
  [2] FORCE_TX_EN — Force Transmit Enable
    0=TSM Idle; 1=TSM executes a TX sequence
0x2C4 END_OF_SEQ reset 0x65646A67 — End of Sequence Control
  [31:24] END_OF_RX_WD — End of RX Warmdown
  [23:16] END_OF_RX_WU — End of RX Warmup
  [15:8] END_OF_TX_WD — End of TX Warmdown
  [7:0] END_OF_TX_WU — End of TX Warmup
0x2C8 TSM_OVRD0 — TSM Override 0
  [31] PLL_RX_LDV_RIPPLE_MUX_EN_OVRD — Override value for PLL_RX_LDV_RIPPLE_MUX_EN
  [30] PLL_RX_LDV_RIPPLE_MUX_EN_OVRD_EN — Override control for PLL_RX_LDV_RIPPLE_MUX_EN
    0=Normal operation; 1=Use the state of PLL_RX_LDV_RIPPLE_MUX_EN_OVRD to override the signal "pll_rx_ldv_ripple_mux_en"
  [29] PLL_LDV_EN_OVRD — Override value for PLL_LDV_EN
  [28] PLL_LDV_EN_OVRD_EN — Override control for PLL_LDV_EN
    0=Normal operation; 1=Use the state of PLL_LDV_EN_OVRD to override the signal "pll_ldv_en"
  [27] PLL_PA_BUF_EN_OVRD — Override value for PLL_PA_BUF_EN
  [26] PLL_PA_BUF_EN_OVRD_EN — Override control for PLL_PA_BUF_EN
    0=Normal operation; 1=Use the state of PLL_PA_BUF_EN_OVRD to override the signal "pll_pa_buf_en"
  [25] PLL_VCO_BUF_TX_EN_OVRD — Override value for PLL_VCO_BUF_TX_EN
  [24] PLL_VCO_BUF_TX_EN_OVRD_EN — Override control for PLL_VCO_BUF_TX_EN
    0=Normal operation; 1=Use the state of PLL_VCO_BUF_TX_EN_OVRD to override the signal "pll_vco_buf_tx_en"
  [23] PLL_VCO_BUF_RX_EN_OVRD — Override value for PLL_VCO_BUF_RX_EN
  [22] PLL_VCO_BUF_RX_EN_OVRD_EN — Override control for PLL_VCO_BUF_RX_EN
    0=Normal operation; 1=Use the state of PLL_VCO_BUF_RX_EN_OVRD to override the signal "pll_vco_buf_rx_en"
  [21] PLL_VCO_EN_OVRD — Override value for PLL_VCO_EN
  [20] PLL_VCO_EN_OVRD_EN — Override control for PLL_VCO_EN
    0=Normal operation; 1=Use the state of PLL_VCO_EN_OVRD to override the signal "pll_vco_en"
  [19] PLL_CYCLE_SLIP_LD_EN_OVRD — Override value for PLL_CYCLE_SLIP_LD_EN
  [18] PLL_CYCLE_SLIP_LD_EN_OVRD_EN — Override control for PLL_CYCLE_SLIP_LD_EN
    0=Normal operation; 1=Use the state of PLL_CYCLE_SLIP_LD_EN_OVRD to override the signal "pll_cycle_slip_ld_en"
  [17] PLL_VCO_AUTOTUNE_EN_OVRD — Override value for PLL_VCO_AUTOTUNE_EN
  [16] PLL_VCO_AUTOTUNE_EN_OVRD_EN — Override control for PLL_VCO_AUTOTUNE_EN
    0=Normal operation; 1=Use the state of PLL_VCO_AUTOTUNE_EN_OVRD to override the signal "pll_vco_autotune_en"
  [15] XTAL_ADC_REF_CLK_EN_OVRD — Override value for XTAL_ADC_REF_CLK_EN
  [14] XTAL_ADC_REF_CLK_EN_OVRD_EN — Override control for XTAL_ADC_REF_CLK_EN
    0=Normal operation; 1=Use the state of XTAL_ADC_REF_CLK_EN_OVRD to override the signal "xtal_adc_ref_clk_en"
  [13] XTAL_PLL_REF_CLK_EN_OVRD — Override value for XTAL_PLL_REF_CLK_EN
  [12] XTAL_PLL_REF_CLK_EN_OVRD_EN — Override control for XTAL_PLL_REF_CLK_EN
    0=Normal operation; 1=Use the state of XTAL_PLL_REF_CLK_EN_OVRD to override the signal "xtal_pll_ref_clk_en"
  [11] ADC_DIG_REG_EN_OVRD — Override value for ADC_DIG_REG_EN
  [10] ADC_DIG_REG_EN_OVRD_EN — Override control for ADC_DIG_REG_EN
    0=Normal operation; 1=Use the state of ADC_DIG_REG_EN_OVRD to override the signal "adc_dig_reg_en"
  [9] ADC_ANA_REG_EN_OVRD — Override value for ADC_ANA_REG_EN
  [8] ADC_ANA_REG_EN_OVRD_EN — Override control for ADC_ANA_REG_EN
    0=Normal operation; 1=Use the state of ADC_ANA_REG_EN_OVRD to override the signal "adc_ana_reg_en"
  [7] TCA_TX_REG_EN_OVRD — Override value for TCA_TX_REG_EN
  [6] TCA_TX_REG_EN_OVRD_EN — Override control for TCA_TX_REG_EN
    0=Normal operation; 1=Use the state of TCA_TX_REG_EN_OVRD to override the signal "tca_tx_reg_en"
  [5] QGEN_REG_EN_OVRD — Override value for QGEN_REG_EN
  [4] QGEN_REG_EN_OVRD_EN — Override control for QGEN_REG_EN
    0=Normal operation; 1=Use the state of QGEN_REG_EN_OVRD to override the signal "qgen_reg_en"
  [3] PLL_VCO_REG_EN_OVRD — Override value for PLL_VCO_REG_EN
  [2] PLL_VCO_REG_EN_OVRD_EN — Override control for PLL_VCO_REG_EN
    0=Normal operation; 1=Use the state of PLL_VCO_REG_EN_OVRD to override the signal "pll_vco_reg_en"
  [1] PLL_REG_EN_OVRD — Override value for PLL_REG_EN
  [0] PLL_REG_EN_OVRD_EN — Override control for PLL_REG_EN
    0=Normal operation; 1=Use the state of PLL_REG_EN_OVRD to override the signal "pll_reg_en"
